# FILTER2 register map
Vendor: Texas Instruments
Peripheral module from a debugger description file (folder UCD3138R032RSM).
Registers are 32-bit, read-write, no defined reset value unless marked. A register's access mark holds for its fields unless they carry their own. Offsets are as the file gives them; lines under a group give offsets from that group; [hi:lo] are bit positions; {n}, {i} and the like mark numbered series; 'fields as' and 'values as' point back to an identical list; <NAME> marks a mode.

## FILTER2 — UCD_FILTER
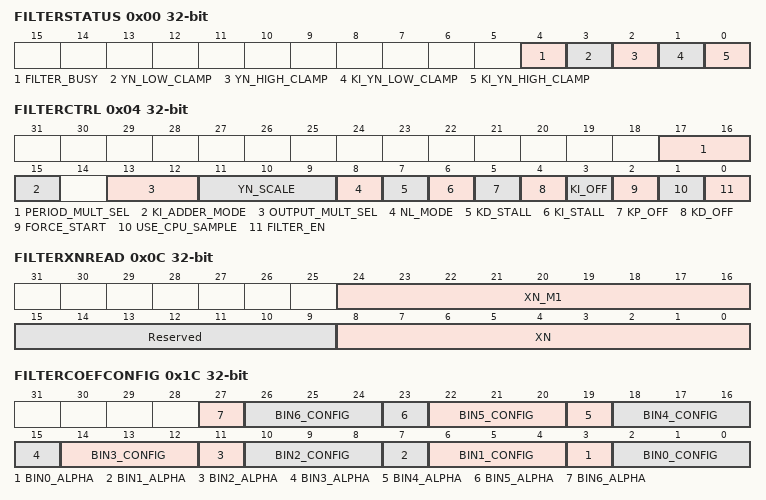
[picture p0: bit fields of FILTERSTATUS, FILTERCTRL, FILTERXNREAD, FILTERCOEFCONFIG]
0x00 FILTERSTATUS ro
  [4] FILTER_BUSY — Filter Busy Indicator
    1=Busy Calculating; 0=Waiting for Data
  [3] YN_LOW_CLAMP — PID Output Low Rail Indicator
    0=NotEqual (PID not equal to low rail); 1=Equal (PID output equal to low rail)
  [2] YN_HIGH_CLAMP — PID Output Low Rail Indicator
    0=notequal (PID not equal to high rail); 1=equal (PID equal to high rail)
  [1] KI_YN_LOW_CLAMP — KI Feedback Low Rail Indicator
    0=notequal (KI Feedback not equal to low rail); 1=equal (KI Feedback equal to low rail)
  [0] KI_YN_HIGH_CLAMP — KI Feedback High Rail Indicator
    0=notequal (KI Feedback not equal to high rail); 1=equal (KI Feedback equal to high rail)
0x04 FILTERCTRL access per field — Filter Status Register
  [17:16] PERIOD_MULT_SEL rw — Selects output multiplicand used for multiplying with filter output to calculate DPWM Period value in Resonant Mode
    0=period (Switching period received from Loop Mux module); 1=KComp received from Loop Mux module
  [15] KI_ADDER_MODE rw — Configures addition of Xn and Xn-1 in Integral branch
    1=Xn + Xn-1 used for addition (Default); 0=Only Xn used for addition (Xn + 0)
  [13:12] OUTPUT_MULT_SEL rw — Selects output multiplicand used for multiplying with filter output to calculate DPWM Duty value
    3=Resonant Duty value received from DPWM Module; 2=Feed_Forwardw (Feed-Forward value received from Loop Mux module); 0=period (Switching period received from Loop Mux module); 1=KComp received from Loop Mux module (Default
  [11:9] YN_SCALE rw — Controls scaling of Yn value to compensate for filter coefficient scaling
    7=left_shifted_1 (Filter output (Yn) left shifted by 1 (Default); 6=left_shifted_2 (Filter output (Yn) left shifted by 2 (Default); 5=left_shifted_3 (Filter output (Yn) left shifted by 3 (Default); 4=left_shifted_4 (Filter output (Yn) left shifted by 4 (Default); 3=right_shifted_3 (Filter output (Yn) right shifted by 3 (Default); 2=right_shifted_2 (Filter output (Yn) right shifted by 2 (Default); 1=right_shifted_1 (Filter output (Yn) right shifted by 1 (Default); 0=period (Filter output (Yn) not scaled (Default))
  [8] NL_MODE rw — Sets non-linear gain table configuration. Coefficient Bin mapping is controlled by Coefficient Configuration Register
    1=Symmetric_mode; 0=Non_symmetric_mode
  [7] KD_STALL rw — Freezes KD Branch, KD_YN remains at current value
    1=stalled (KD_YN stalled at present value); 0=recalculated (Kd_YN recalculated on each filter update (Default))
  [6] KI_STALL rw — Freezes KI Branch, KI_YN remains at current value
    1=stalled (KI_YN stalled at present value); 0=recalculated (KI_YN recalculated on each filter update (Default))
  [5] KP_OFF rw — Turns off the KP branch
    1=OFF (KP branch turned off); 0=ON (KP branch calculating new outputs (Default))
  [4] KD_OFF rw — Turns off the KP branch
    1=OFF (KD branch turned off); 0=ON (KD branch calculating new outputs (Default))
  [3] KI_OFF rw — Turns off the KP branch
    1=OFF (Ki branch turned off); 0=ON (Ki branch calculating new outputs (Default))
  [2] FORCE_START rw — Initiates a filter calculation under firmware control
    1=started (calculation started); 0=not_started (No calculation started (Default)
  [1] USE_CPU_SAMPLE rw — IForces filter to use error sample from CPU XN register
    1=CPU Mode, input data based on CPU XN register; 0=Filter Mode, input data received from EADC (Default)
  [0] FILTER_EN rw — Filter Enable
    1=Enables Filter operation (Default); 0=Disables Filter operation
0x08 FILTERCPUXN — CPU XN Register (CPUXN)
  [8:0] CPU_SAMPLE — Forced Xn value, allows processor to use filter as ALU. Set Bit 2 of Filter Control Register to force CPU_SAMPLE as input to Filter
0x0C FILTERXNREAD ro — Filter Status Register
  [24:16] XN_M1 — 9-bit signed XN_M1 register value, read-only
  [15:9] Reserved — not mentioned
  [8:0] XN — 9-bit signed XN register value, read-only
0x10 FILTERKIYNREAD ro
  [23:0] KI_YN — 24-bit signed KI_YN register value, read-only
0x14 FILTERKDYNREAD ro
  [23:0] KD_YN — 24-bit signed KD_YN register value, read-only
0x18 FILTERYNREAD ro
  [23:0] YN — 24-bit signed YN register value, read-only
0x1C FILTERCOEFCONFIG — Coefficient Configuration Register
  [4n+3] BIN{n}_ALPHA (n=0..6) — Selects which alpha value to use in Bin {n} of Non-Linear Table. These bits are shadowed and updated to filter when filter is not processing an EADC sample
    1=Bank 1 KD Alpha (KD_ALPHA_1) selected; 0=Bank 0 KD Alpha (KD_ALPHA_0) selected (Default)
  [4n+2:4n] BIN{n}_CONFIG (n=0..6) — Selects which coefficient set to place in Bin {n} of Non-Linear Table. These bits are shadowed and updated to filter when filter is not processing an EADC sample.
    6=Set_G (Coefficient Set G Selected (Default)); 5=Set_F (Coefficient Set F Selected (Default)); 4=Set_E (Coefficient Set E Selected (Default)); 3=Set_D (Coefficient Set D Selected (Default)); 2=Set_C (Coefficient Set C Selected (Default)); 1=Set_B (Coefficient Set B Selected (Default)); 0=Set_A (Coefficient Set A Selected (Default))
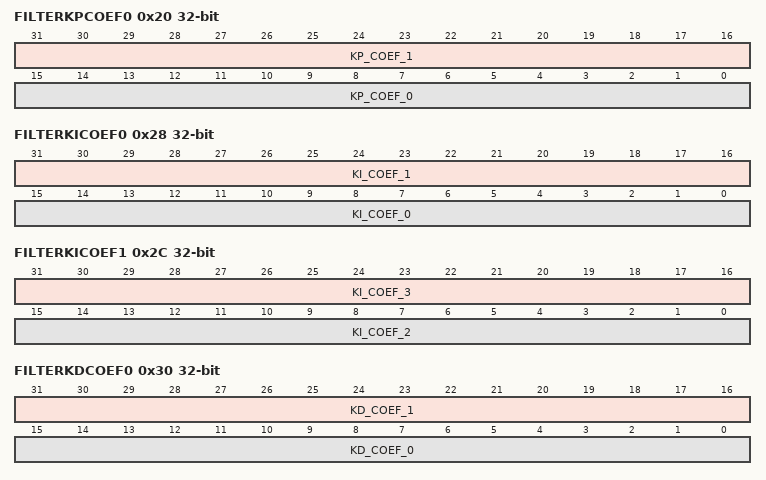
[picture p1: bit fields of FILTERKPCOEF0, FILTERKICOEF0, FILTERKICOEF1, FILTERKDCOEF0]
0x20 FILTERKPCOEF0 — Filter KP Coefficient 0 Register
  [31:16] KP_COEF_1 — KP Coefficient 1, 16-bit signed coefficient, configurable to any bin using the Coefficient Control Register
  [15:0] KP_COEF_0 — KP Coefficient 0, 16-bit signed coefficient, configurable to any bin using the Coefficient Control Register
0x24 FILTERKPCOEF1 — Filter KP Coefficient 1 Register
  [15:0] KP_COEF_2 — KP Coefficient 2, 16-bit signed coefficient, configurable to any bin using the Coefficient Control Register
0x28 FILTERKICOEF0 — Filter KI Coefficient 0 Register
  [31:16] KI_COEF_1 — KI Coefficient 1, 16-bit signed coefficient, configurable to any bin using the Coefficient Control Register
  [15:0] KI_COEF_0 — KI Coefficient 0, 16-bit signed coefficient, configurable to any bin using the Coefficient Control Register
0x2C FILTERKICOEF1 — Filter KI Coefficient 0 Register
  [31:16] KI_COEF_3 — KI Coefficient 3, 16-bit signed coefficient, configurable to any bin using the Coefficient Control Register
  [15:0] KI_COEF_2 — KI Coefficient 2, 16-bit signed coefficient, configurable to any bin using the Coefficient Control Register
0x30 FILTERKDCOEF0 — Filter KD Coefficient 0 Register
  [31:16] KD_COEF_1 — KD Coefficient 1, 16-bit signed coefficient, configurable to any bin using the Coefficient Control Register
  [15:0] KD_COEF_0 — KD Coefficient 0, 16-bit signed coefficient, configurable to any bin using the Coefficient Control Register
0x34 FILTERKDCOEF1 — Filter KD Coefficient 0 Register
  [15:0] KD_COEF_2 — KD Coefficient 2, 16-bit signed coefficient, configurable to any bin using the Coefficient Control Register
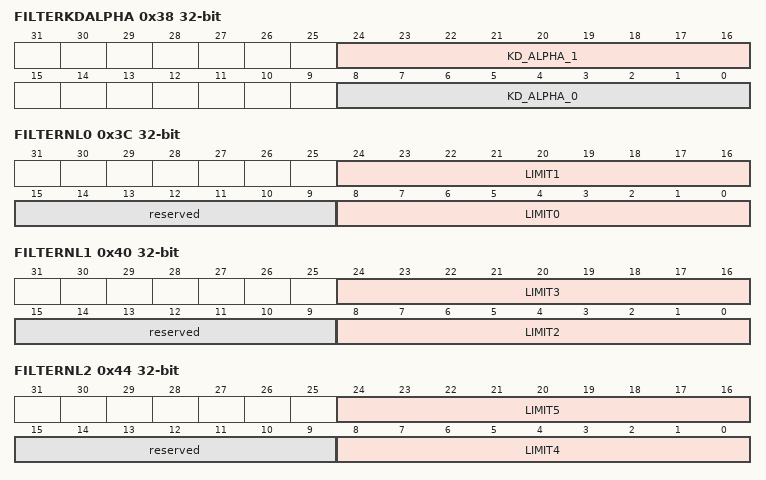
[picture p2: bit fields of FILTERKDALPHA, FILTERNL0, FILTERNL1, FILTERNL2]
0x38 FILTERKDALPHA access per field
  [24:16] KD_ALPHA_1 rw — Bank 1 KD Alpha, 9-bit signed value, configurable to any bin using the Coefficient Control Register
  [8:0] KD_ALPHA_0 rw — Bank 0 KD Alpha, 9-bit signed value, configurable to any bin using the Coefficient Control Register
0x3C FILTERNL0 access per field — Filter Nonlinear Limit Register 0
  [24:16] LIMIT1 rw — Configures LIMIT1 in Nonlinear Coefficient tables
  [15:9] reserved ro — not mentioned
  [8:0] LIMIT0 rw — Configures LIMIT0 in Nonlinear Coefficient tables
0x40 FILTERNL1 access per field — Filter Nonlinear Limit Register 1
  [24:16] LIMIT3 rw — Configures LIMIT3 in Nonlinear Coefficient tables
  [15:9] reserved ro — not mentioned
  [8:0] LIMIT2 rw — Configures LIMIT2 in Nonlinear Coefficient tables
0x44 FILTERNL2 access per field — Filter Nonlinear Limit Register 1
  [24:16] LIMIT5 rw — Configures LIMIT5 in Nonlinear Coefficient tables
  [15:9] reserved ro — not mentioned
  [8:0] LIMIT4 rw — Configures LIMIT4 in Nonlinear Coefficient tables
0x48 FILTERKICLPHI — Filter Nonlinear Limit Register 1
  [23:0] KI_CLAMP_HIGH — Sets the upper limit of KI_YN value. If calculated KI_YN exceeds this threshold, the KI_YN register will be set to KI_CLAMP_HIGH
0x4C FILTERKICLPLO — Filter KI Feedback Clamp Low Register
  [23:0] KI_CLAMP_LOW — Sets the lower limit of KI_YN value. If calculated KI_YN falls below this threshold, the KI_YN register will be set to KI_CLAMP_LOW
0x50 FILTERYNCLPHI — Filter YN Clamp High Register
  [23:0] YN_CLAMP_HIGH — Sets the upper limit of YN value. If calculated YN exceeds this threshold, the YN register will be set to YN_CLAMP_HIGH
0x54 FILTERYNCLPLO — Filter KI Feedback Clamp Low Register
  [23:0] YN_CLAMP_LOW — Sets the lower limit of YN value. If calculated YN falls below this threshold, the YN register will be set to YN_CLAMP_LOW
0x58 FILTEROCLPHI — Filter Output Clamp HIGH Register
  [17:0] OUTPUT_CLAMP_HIGH — Sets the upper limit of filter output value. If calculated filter output exceeds this threshold, the filter output will be set to OUTPUT_CLAMP_HIGH
0x5C FILTEROCLPLO — Filter Output Clamp Low Register
  [17:0] OUTPUT_CLAMP_LOW — Sets the lower limit of filter output value. If calculated filter output falls below this threshold, the filter output will be set to OUTPUT_CLAMP_LOW
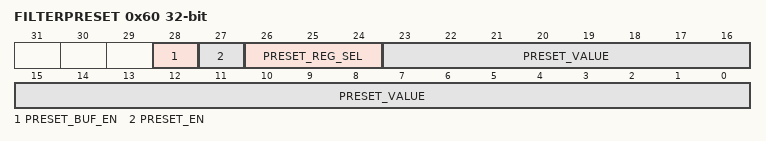
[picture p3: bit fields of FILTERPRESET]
0x60 FILTERPRESET
  [28] PRESET_BUF_EN — Set to 1 to initiate write of internal filter buffer register (Self cleared by hardware after successful programming)
  [27] PRESET_EN — Set to initiate write of internal filter register (Self cleared by hardware after successful programming)
  [26:24] PRESET_REG_SEL — Selects internal filter register to preset by processor
    4=filter_data (18-bit Filter Data Register (after multiplication)); 3=YN (YN Register (only bits 10:0 of PRESET_VALUE will be programmed into register)); 2=KD_YN (KD_YN Register (only bits 10:0 of PRESET_VALUE will be programmed into register)); 1=KI_YN (KI_YN Register (only bits 10:0 of PRESET_VALUE will be programmed into register)); 0=XN_M1 (XN_M1 Register (only bits 10:0 of PRESET_VALUE will be programmed into register))
  [23:0] PRESET_VALUE — Value to preset into selected register
0x64 FILTERPOCLPHI — Filter Period Clamp HIGH Register
  [17:0] PERIOD_OUTPUT_CLAMP_HIGH — Sets the upper limit of filter period value. If calculated filter period exceeds this threshold, the filter period will be set to PERIOD_OUTPUT_CLAMP_HIGH
0x68 FILTERPOCLPLO — Filter Period Clamp Low Register
  [17:0] PERIOD_OUTPUT_CLAMP_LOW — Sets the lower limit of filter period value. If calculated filter period falls below this threshold, the filter period will be set to PERIOD_OUTPUT_CLAMP_LOW
